# S6E2C5 register map
File version: 1.0
Registers are 32-bit, read-write, reset 0x0 unless marked. A register's access mark holds for its fields unless they carry their own. Offsets are from the block's base; [hi:lo] are bit positions; {n}, {i} and the like mark numbered series.

## FLASH_IF — Flash Memory
Base 0x40000000
0x00 FASZR reset 0x2 — Flash Access Size Register
  [1:0] ASZ — Access Size
0x04 FRWTR reset 0x2 — Flash Read Wait Register
  [1:0] RWT — Read Wait Cycle
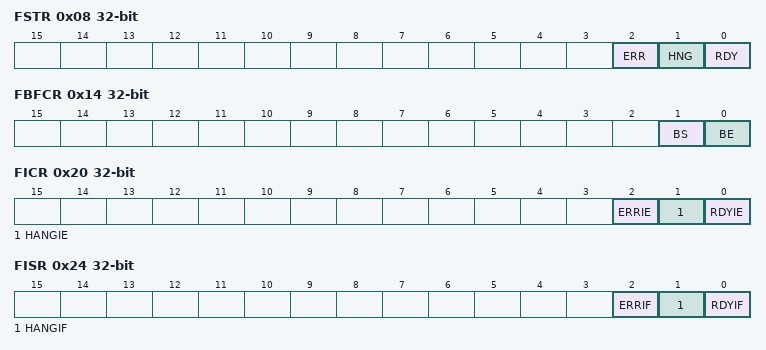
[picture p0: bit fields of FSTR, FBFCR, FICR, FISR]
0x08 FSTR ro — Flash Status Register
  [2] ERR rw — Flash ECC Error
  [1] HNG — Flash Hang
  [0] RDY — Flash Rdy
0x10 FSYNDN — Flash Sync Down Register
  [2:0] SD — Sync Down
0x14 FBFCR — Flash Buffer Control Register
  [1] BS ro — Buffer Status
  [0] BE — Buffer Enable
0x20 FICR — Flash Interrupt Control Register
  [2] ERRIE — Flash ECC Error Interrupt Enable
  [1] HANGIE — Flash HANG Interrupt Enable
  [0] RDYIE — Flash RDY Interrupt Enable
0x24 FISR — Flash Interrupt Status Register
  [2] ERRIF ro — Flash ECC Error Interrupt Flag
  [1] HANGIF ro — Flash HANG Interrupt Flag
  [0] RDYIF ro — Flash RDY Interrupt Flag
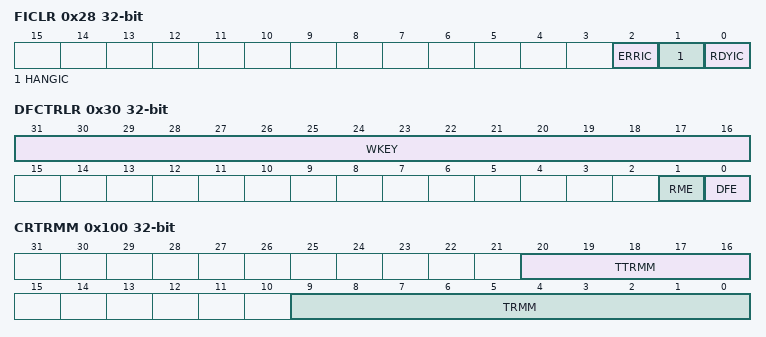
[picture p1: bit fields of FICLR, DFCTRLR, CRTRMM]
0x28 FICLR wo — Flash Interrupt Clear Register
  [2] ERRIC rw — Flash ECC Error Interrupt Clear
  [1] HANGIC rw — Flash HANG Interrupt Clear
  [0] RDYIC rw — Flash RDY Interrupt Clear
0x30 DFCTRLR — Dual Flash mode Control Register
  [31:16] WKEY — Write Key
  [1] RME — Re-Map Enable
  [0] DFE — Dual Flash mode Enable
0x100 CRTRMM ro reset not defined — CR Trimming Data Mirror Register
  [20:16] TTRMM — Temperature CR Trimming Data Mirror
  [9:0] TRMM — CR Trimming Data Mirror
{0x10C+4i} FGPDM{i} ro (i=1..4) — Flash General Purpose Data Mirror Register{i}
  [31:0] GPD{i} — General Purpose Data{i}

## DUALFLASH_IF — Dual Flash Memory
Base 0x40000400
0x00 DFASZR reset 0x2 — Dual Flash Access Size Register
  [1:0] DASZ — Dual Flash Access Size
0x04 DFRWTR reset 0x3 — Dual Flash Read Wait Register
  [1:0] DRWT — Dual Flash Read Wait Cycle
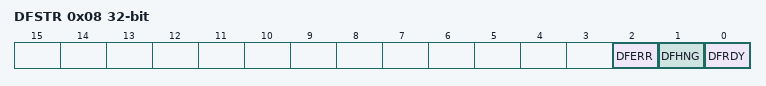
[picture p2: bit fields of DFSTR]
0x08 DFSTR — Dual Flash ECC Error
  [2] DFERR — Dual Flash ECC Error
  [1] DFHNG ro — Dual Flash Hang
  [0] DFRDY ro — Dual Flash Rdy

## UNIQUE_ID
Base 0x40000200
0x00 UIDR0 ro — Unique ID Register 0
  [31:4] UID — Unique ID 27 through 0
0x04 UIDR1 ro — Unique ID Register 1
  [12:0] UID — Unique ID 40 through 28

## ECC_CAPTURE — ECC Capture Address
Base 0x40000300
0x00 FERRAD ro — Flash ECC Error Address Capture Register
  [22:0] ERRAD — Flash ECC Error Address Capture

## CRTRIM — CR Trimming Registers
Base 0x4002E000
0x00 MCR_PSR 8-bit reset 0x1 — High-speed CR oscillation Frequency Division Setup Register
  [2:0] CSR — High-speed CR oscillation frequency division ratio setting bits
0x04 MCR_FTRM 16-bit reset 0x1EF — High-speed CR oscillation Frequency Trimming Register
  [9:0] TRD — Frequency trimming setup bits
0x08 MCR_TTRM 8-bit reset 0x10 — High-speed CR oscillation Temperature Trimming Register
  [4:0] TRT — Temperature trimming setup bits
0x0C MCR_RLR reset 0x1 — High-Speed CR Oscillation Register Write-Protect Register
  [31:0] TRMLCK — Register write-protect bits

## SWWDT — Software Watchdog Timer
Base 0x40012000
0x00 WDOGLOAD reset 0xFFFFFFFF — Software Watchdog Timer Load Register
0x04 WDOGVALUE ro reset 0xFFFFFFFF — Software Watchdog Timer Value Register
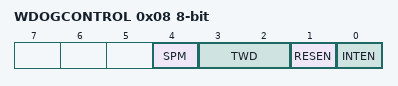
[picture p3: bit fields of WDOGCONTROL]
0x08 WDOGCONTROL 8-bit — Software Watchdog Timer Control Register
  [4] SPM — Software Watchdog window watchdog mode enable bit
  [3:2] TWD — Timing window setting bit of the software watchdog
  [1] RESEN — Reset enable bit of the software watchdog
  [0] INTEN — Interrupt and counter enable bit of the software watchdog
0x0C WDOGINTCLR reset 0xFFFFFFFF — Software Watchdog Timer Clear Register
0x10 WDOGRIS 8-bit ro — Software Watchdog Timer Interrupt Status Register
  [0] RIS — Software watchdog interrupt status bit
0x18 WDOGSPMC 8-bit — Software Watchdog Timer Window Watchdog Mode Control Register
  [0] TGR ro — Software watchdog trigger type bit
0xC00 WDOGLOCK — Software Watchdog Timer Lock Register

## Notices in the file
Copyright (C) 2014 Spansion LLC. All Rights Reserved.
This software is owned and published by:
Spansion LLC, 915 DeGuigne Dr. Sunnyvale, CA  94088-3453 ("Spansion").
BY DOWNLOADING, INSTALLING OR USING THIS SOFTWARE, YOU AGREE TO BE BOUND
BY ALL THE TERMS AND CONDITIONS OF THIS AGREEMENT.
This software contains source code for use with Spansion
components. This software is licensed by Spansion to be adapted only
for use in systems utilizing Spansion components. Spansion shall not be
responsible for misuse or illegal use of this software for devices not
supported herein.  Spansion is providing this software "AS IS" and will
not be responsible for issues arising from incorrect user implementation
of the software.
SPANSION MAKES NO WARRANTY, EXPRESS OR IMPLIED, ARISING BY LAW OR OTHERWISE,
REGARDING THE SOFTWARE (INCLUDING ANY ACOOMPANYING WRITTEN MATERIALS),
ITS PERFORMANCE OR SUITABILITY FOR YOUR INTENDED USE, INCLUDING,
WITHOUT LIMITATION, THE IMPLIED WARRANTY OF MERCHANTABILITY, THE IMPLIED
WARRANTY OF FITNESS FOR A PARTICULAR PURPOSE OR USE, AND THE IMPLIED
WARRANTY OF NONINFRINGEMENT.
SPANSION SHALL HAVE NO LIABILITY (WHETHER IN CONTRACT, WARRANTY, TORT,
NEGLIGENCE OR OTHERWISE) FOR ANY DAMAGES WHATSOEVER (INCLUDING, WITHOUT
LIMITATION, DAMAGES FOR LOSS OF BUSINESS PROFITS, BUSINESS INTERRUPTION,
LOSS OF BUSINESS INFORMATION, OR OTHER PECUNIARY LOSS) ARISING FROM USE OR
INABILITY TO USE THE SOFTWARE, INCLUDING, WITHOUT LIMITATION, ANY DIRECT,
INDIRECT, INCIDENTAL, SPECIAL OR CONSEQUENTIAL DAMAGES OR LOSS OF DATA,
SAVINGS OR PROFITS,
EVEN IF SPANSION HAS BEEN ADVISED OF THE POSSIBILITY OF SUCH DAMAGES.
YOU ASSUME ALL RESPONSIBILITIES FOR SELECTION OF THE SOFTWARE TO ACHIEVE YOUR
INTENDED RESULTS, AND FOR THE INSTALLATION OF, USE OF, AND RESULTS OBTAINED
FROM, THE SOFTWARE.
This software may be replicated in part or whole for the licensed use,
with the restriction that this Disclaimer and Copyright notice must be
included with each copy of this software, whether used in part or whole,
at all times.
